VERSION ""

NS_ :

BS_:

BU_: XXX

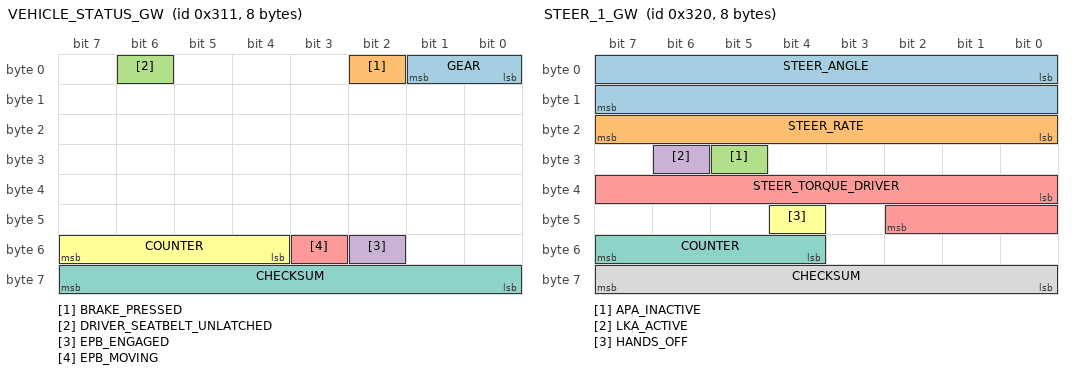
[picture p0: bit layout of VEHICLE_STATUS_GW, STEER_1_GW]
BO_ 785 VEHICLE_STATUS_GW: 8 XXX
 SG_ GEAR : 0|2@1+ (1,0) [0|3] "" XXX
 SG_ BRAKE_PRESSED : 2|1@1+ (1,0) [0|1] "" XXX
 SG_ DRIVER_SEATBELT_UNLATCHED : 6|1@1+ (1,0) [0|1] "" XXX
 SG_ EPB_ENGAGED : 50|1@1+ (1,0) [0|1] "" XXX
 SG_ EPB_MOVING : 51|1@1+ (1,0) [0|1] "" XXX
 SG_ COUNTER : 52|4@1+ (1,0) [0|15] "" XXX
 SG_ CHECKSUM : 56|8@1+ (1,0) [0|255] "" XXX

BO_ 800 STEER_1_GW: 8 XXX
 SG_ STEER_ANGLE : 0|16@1+ (-0.1,900) [-900|900] "deg" XXX
 SG_ STEER_RATE : 16|8@1+ (4,0) [0|1020] "deg/s" XXX
 SG_ APA_INACTIVE : 29|1@1+ (1,0) [0|1] "" XXX
 SG_ LKA_ACTIVE : 30|1@1+ (1,0) [0|1] "" XXX
 SG_ STEER_TORQUE_DRIVER : 32|11@1+ (-1,1000) [-1000|1000] "" XXX
 SG_ HANDS_OFF : 44|1@1+ (1,0) [0|1] "" XXX
 SG_ COUNTER : 52|4@1+ (1,0) [0|15] "" XXX
 SG_ CHECKSUM : 56|8@1+ (1,0) [0|255] "" XXX

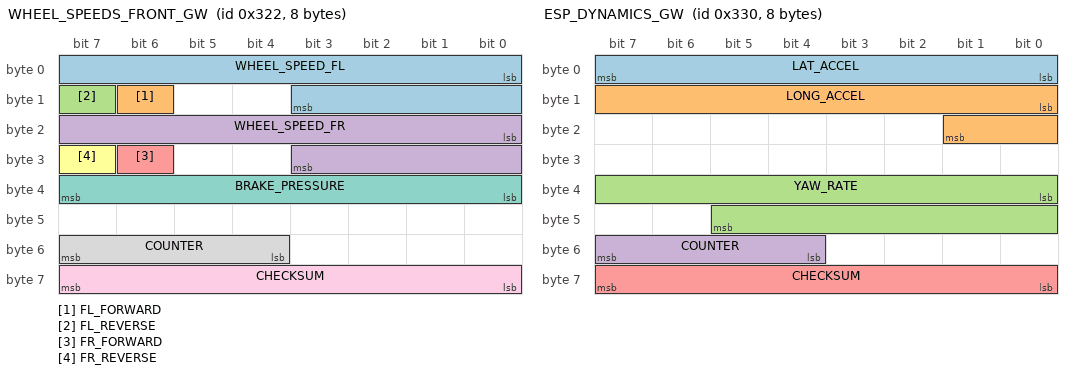
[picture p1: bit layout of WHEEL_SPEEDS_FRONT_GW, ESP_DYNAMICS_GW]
BO_ 802 WHEEL_SPEEDS_FRONT_GW: 8 XXX
 SG_ WHEEL_SPEED_FL : 0|12@1+ (0.05625,0) [0|230.34] "km/h" XXX
 SG_ FL_FORWARD : 14|1@1+ (1,0) [0|1] "" XXX
 SG_ FL_REVERSE : 15|1@1+ (1,0) [0|1] "" XXX
 SG_ WHEEL_SPEED_FR : 16|12@1+ (0.05625,0) [0|230.34] "km/h" XXX
 SG_ FR_FORWARD : 30|1@1+ (1,0) [0|1] "" XXX
 SG_ FR_REVERSE : 31|1@1+ (1,0) [0|1] "" XXX
 SG_ BRAKE_PRESSURE : 32|8@1+ (1,0) [0|255] "" XXX
 SG_ COUNTER : 52|4@1+ (1,0) [0|15] "" XXX
 SG_ CHECKSUM : 56|8@1+ (1,0) [0|255] "" XXX

BO_ 816 ESP_DYNAMICS_GW: 8 XXX
 SG_ LAT_ACCEL : 0|8@1+ (0.1,-12.8) [-12.8|12.7] "m/s2" XXX
 SG_ LONG_ACCEL : 8|10@1+ (0.03125,-16) [-16|15.97] "m/s2" XXX
 SG_ YAW_RATE : 32|14@1+ (0.01,-81.92) [-81.92|81.91] "deg/s" XXX
 SG_ COUNTER : 52|4@1+ (1,0) [0|15] "" XXX
 SG_ CHECKSUM : 56|8@1+ (1,0) [0|255] "" XXX

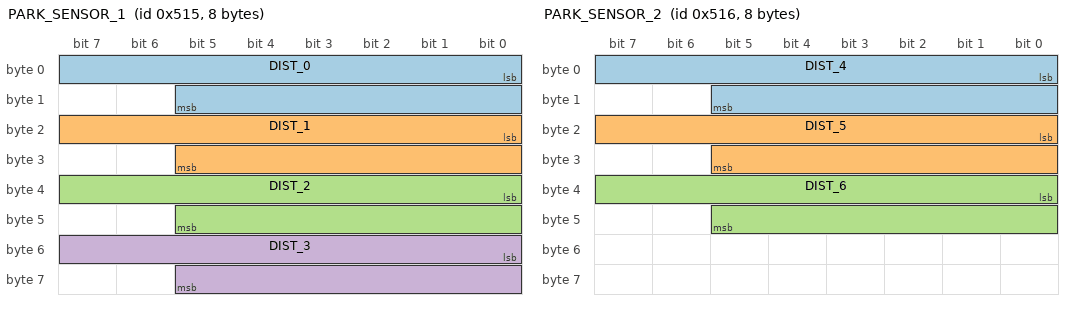
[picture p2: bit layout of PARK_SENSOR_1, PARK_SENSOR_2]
BO_ 1301 PARK_SENSOR_1: 8 XXX
 SG_ DIST_0 : 0|14@1+ (0.001,0) [0|16.383] "m" XXX
 SG_ DIST_1 : 16|14@1+ (0.001,0) [0|16.383] "m" XXX
 SG_ DIST_2 : 32|14@1+ (0.001,0) [0|16.383] "m" XXX
 SG_ DIST_3 : 48|14@1+ (0.001,0) [0|16.383] "m" XXX

BO_ 1302 PARK_SENSOR_2: 8 XXX
 SG_ DIST_4 : 0|14@1+ (0.001,0) [0|16.383] "m" XXX
 SG_ DIST_5 : 16|14@1+ (0.001,0) [0|16.383] "m" XXX
 SG_ DIST_6 : 32|14@1+ (0.001,0) [0|16.383] "m" XXX

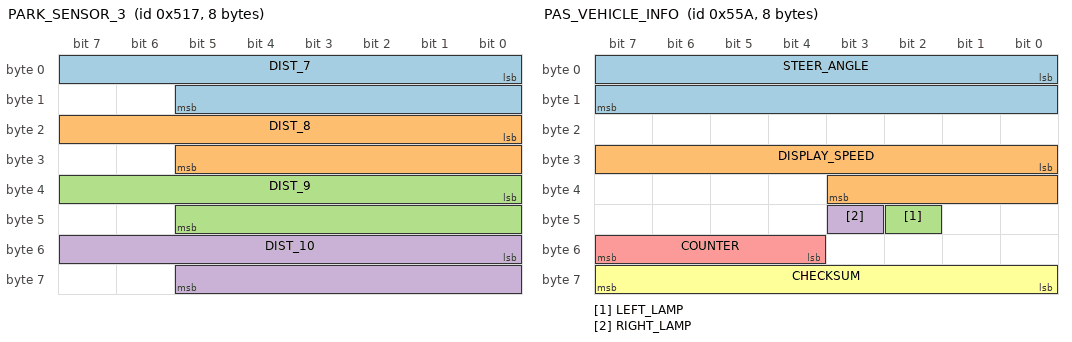
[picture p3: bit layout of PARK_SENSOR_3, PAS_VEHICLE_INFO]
BO_ 1303 PARK_SENSOR_3: 8 XXX
 SG_ DIST_7 : 0|14@1+ (0.001,0) [0|16.383] "m" XXX
 SG_ DIST_8 : 16|14@1+ (0.001,0) [0|16.383] "m" XXX
 SG_ DIST_9 : 32|14@1+ (0.001,0) [0|16.383] "m" XXX
 SG_ DIST_10 : 48|14@1+ (0.001,0) [0|16.383] "m" XXX

BO_ 1370 PAS_VEHICLE_INFO: 8 XXX
 SG_ STEER_ANGLE : 0|16@1+ (-0.1,900) [-900|900] "deg" XXX
 SG_ DISPLAY_SPEED : 24|12@1+ (0.1,-180) [0|229.5] "km/h" XXX
 SG_ LEFT_LAMP : 42|1@1+ (1,0) [0|1] "" XXX
 SG_ RIGHT_LAMP : 43|1@1+ (1,0) [0|1] "" XXX
 SG_ COUNTER : 52|4@1+ (1,0) [0|15] "" XXX
 SG_ CHECKSUM : 56|8@1+ (1,0) [0|255] "" XXX

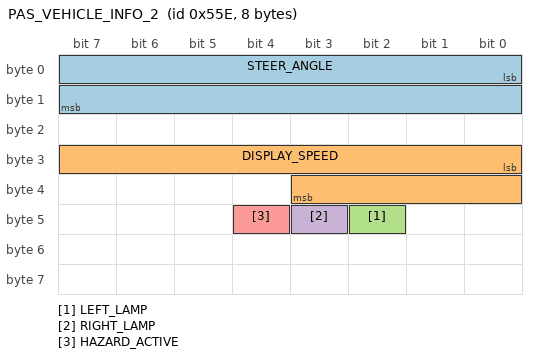
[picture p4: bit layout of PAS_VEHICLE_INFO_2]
BO_ 1374 PAS_VEHICLE_INFO_2: 8 XXX
 SG_ STEER_ANGLE : 0|16@1+ (-0.1,900) [-900|900] "deg" XXX
 SG_ DISPLAY_SPEED : 24|12@1+ (0.1,-180) [0|229.5] "km/h" XXX
 SG_ LEFT_LAMP : 42|1@1+ (1,0) [0|1] "" XXX
 SG_ RIGHT_LAMP : 43|1@1+ (1,0) [0|1] "" XXX
 SG_ HAZARD_ACTIVE : 44|1@1+ (1,0) [0|1] "" XXX

VAL_ 785 GEAR 3 "D" 2 "N" 1 "R" ;
